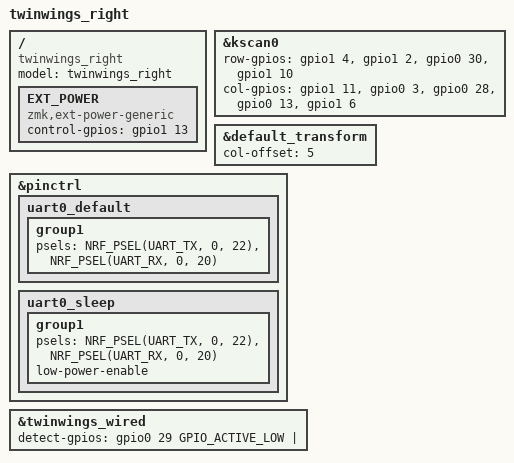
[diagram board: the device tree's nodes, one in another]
/*
 * Copyright (c) 2026 Nicolas Munnich
 * SPDX-License-Identifier: MIT
 */

#include "twinwings.dtsi"

/ {
    model = "twinwings_right";
    compatible = "twinwings_right";

    EXT_POWER {
        compatible = "zmk,ext-power-generic";
        control-gpios = <&gpio1 13 GPIO_ACTIVE_HIGH>;
    };

};

&kscan0 {
    row-gpios
        = <&gpio1 4 (GPIO_ACTIVE_HIGH | GPIO_PULL_DOWN)>
        , <&gpio1 2 (GPIO_ACTIVE_HIGH | GPIO_PULL_DOWN)>
        , <&gpio0 30 (GPIO_ACTIVE_HIGH | GPIO_PULL_DOWN)>
        , <&gpio1 10 (GPIO_ACTIVE_HIGH | GPIO_PULL_DOWN)>
        ;
    col-gpios
        = <&gpio1 11 GPIO_ACTIVE_HIGH>
        , <&gpio0 3 GPIO_ACTIVE_HIGH>
        , <&gpio0 28 GPIO_ACTIVE_HIGH>
        , <&gpio0 13 GPIO_ACTIVE_HIGH>
        , <&gpio1 6 GPIO_ACTIVE_HIGH>
        ;
};

&default_transform {
    col-offset = <5>;
};

&pinctrl {
    uart0_default: uart0_default {
        group1 {
            psels = <NRF_PSEL(UART_TX, 0, 22)>, 
                    <NRF_PSEL(UART_RX, 0, 20)>; 
        };
    };

    uart0_sleep: uart0_sleep {
        group1 {
            psels = <NRF_PSEL(UART_TX, 0, 22)>,
                    <NRF_PSEL(UART_RX, 0, 20)>;
            low-power-enable;
        };
    };
};

&twinwings_wired {
    detect-gpios = <&gpio0 29 GPIO_ACTIVE_LOW | GPIO_PULL_UP>;
};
